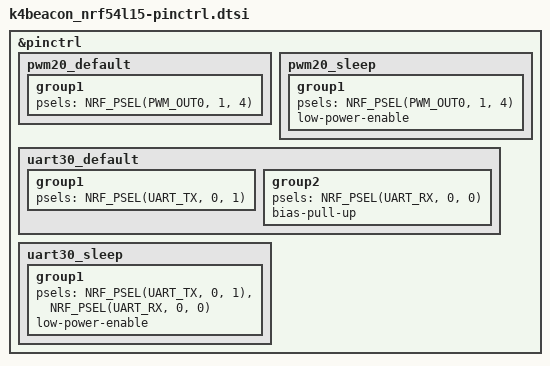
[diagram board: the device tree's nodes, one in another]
/*
 * SPDX-License-Identifier: Apache-2.0
 *
 * Pins read off the signal table of K4Beacon_54L15 Rev V1.0
 * (boards/kkm/K4_54L15/K4_nRF54L15_SCH V1.1.pdf):
 *
 *   LED1  P1.04/AIN0      LED2  P2.03      KEY  P0.04
 *   RXD   P0.00           TXD   P0.01
 *   SCL   P1.08/CLK16M    SDA   P1.06/AIN2
 *   INT1  P1.13/AIN6      INT2  P1.14/AIN7
 *
 * NOT the pinout in KKM's own nrf54l15dk overlay, which is the K7's
 * (P1.10/11/12, active low, KEY on P0.02) and lights nothing on a K4.
 *
 * UART30, not UART20. P0.00/P0.01 are in the nRF54L15's low-power domain,
 * which only the "30" peripheral instances can reach. A uart20 on these pins
 * builds cleanly and then does nothing at all.
 */

&pinctrl {
	/*
	 * LED1 only. LED2 is on P2.03 — the MCU domain — which the LP-domain
	 * PWM peripherals cannot drive, so it is GPIO on/off and appears in
	 * the gpio-leds node instead.
	 */
	/omit-if-no-ref/ pwm20_default: pwm20_default {
		group1 {
			psels = <NRF_PSEL(PWM_OUT0, 1, 4)>;
		};
	};

	/omit-if-no-ref/ pwm20_sleep: pwm20_sleep {
		group1 {
			psels = <NRF_PSEL(PWM_OUT0, 1, 4)>;
			low-power-enable;
		};
	};

	/omit-if-no-ref/ uart30_default: uart30_default {
		group1 {
			psels = <NRF_PSEL(UART_TX, 0, 1)>;
		};
		group2 {
			psels = <NRF_PSEL(UART_RX, 0, 0)>;
			bias-pull-up;
		};
	};

	/omit-if-no-ref/ uart30_sleep: uart30_sleep {
		group1 {
			psels = <NRF_PSEL(UART_TX, 0, 1)>,
				<NRF_PSEL(UART_RX, 0, 0)>;
			low-power-enable;
		};
	};
};
